# APM32F446 register map
File version: 1.0
CPU: CM4 r0p1, little endian, MPU, FPU, 4 interrupt priority bits
Registers are 32-bit, read-write, reset 0x0 unless marked. A register's access mark holds for its fields unless they carry their own. Offsets are from the block's base; [hi:lo] are bit positions; {n}, {i} and the like mark numbered series.

## CSE_PRAM
Base 0x14001000
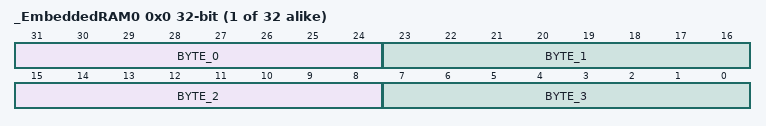
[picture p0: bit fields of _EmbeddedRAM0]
{0x0+4i} _EmbeddedRAM{i} (CSE_PRAM view) (i=0..31) — CSE PRAM {i} Register
  [31-8n:24-8n] BYTE_{n} (n=0..3) — Data byte {n} of Rx/Tx frame.
{0x0+4i} _EmbeddedRAM{i}LL 8-bit (CSE_PRAM view) (i=0..31) — CSE PRAM{i}LL register.
  [7:0] RAM_LL — RAM_LL stores the first 8 bits of the 32 bit CRC
{0x1+4i} _EmbeddedRAM{i}LU 8-bit (i=0..31) — CSE PRAM{i}LU register.
  [7:0] RAM_LU — RAM_LU stores the second 8 bits of the 32 bit CRC
{0x2+4i} _EmbeddedRAM{i}HL 8-bit (i=0..31) — CSE PRAM{i}HL register.
  [7:0] RAM_HL — RAM_HL stores the third 8 bits of the 32 bit CRC
{0x3+4i} _EmbeddedRAM{i}HU 8-bit (i=0..31) — CSE PRAM{i}HU register.
  [7:0] RAM_HU — RAM_HU stores the fourth 8 bits of the 32 bit CRC

## EREP — Error Reporting
Base 0x40018000
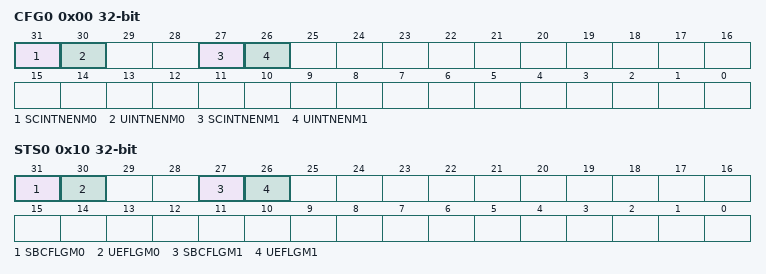
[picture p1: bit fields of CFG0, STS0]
0x00 CFG0 — Configure Register 0
  [31] SCINTNENM0 — Memory 0 Single-Bit Correction Interrupt Notification Enable
    0=Interrupt notification of Memory 0 single-bit correction events is disabled; 1=Interrupt notification of Memory 0 single-bit correction events is enabled
  [30] UINTNENM0 — Memory 0 Uncorrectable Interrupt Notification Enable
    0=Interrupt notification of Memory 0 non-correctable error events is disabled; 1=Interrupt notification of Memory 0 non-correctable error events is enabled
  [27] SCINTNENM1 — Memory 1 Single-Bit Correction Interrupt Notification Enable
    0=Interrupt notification of Memory 1 single-bit correction events is disabled; 1=Interrupt notification of Memory 1 single-bit correction events is enabled
  [26] UINTNENM1 — Memory 1 Uncorrectable Interrupt Notification Enable
    0=Interrupt notification of Memory 1 non-correctable error events is disabled; 1=Interrupt notification of Memory 1 non-correctable error events is enabled
0x10 STS0 — Status Register 0
  [31] SBCFLGM0 — Memory 0 Single-Bit Correction Event Flag
    0=No single-bit correction event on Memory 0 detected; 1=Single-bit correction event on Memory 0 detected
  [30] UEFLGM0 — Memory 0 Uncorrectable Error Event Flag
    0=No non-correctable error event on Memory 0 detected; 1=Non-correctable error event on Memory 0 detected
  [27] SBCFLGM1 — Memory 1 Single-Bit Correction Event Flag
    0=No single-bit correction event on Memory 1 detected; 1=Single-bit correction event on Memory 1 detected
  [26] UEFLGM1 — Memory 1 Uncorrectable Error Event Flag
    0=No non-correctable error event on Memory 1 detected; 1=Non-correctable error event on Memory 1 detected
0x100 EADDR0 ro — Error Address Register 0
  [31:0] EADDR
0x110 EADDR1 ro — Error Address Register 1
  [31:0] EADDR

## EINJ — Error Injection
Base 0x40019000
0x00 CFG — Configure Register
  [0] GEINJEN — Global Error Injection Function Enable
    0=Disabled; 1=Enabled
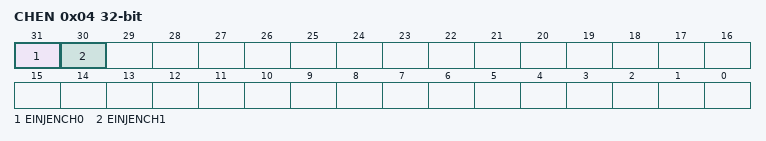
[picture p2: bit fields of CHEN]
0x04 CHEN — Channel Enable Register
  [31] EINJENCH0 — Error Injection CH0 Enable
    0=Error injection is disabled on Error Injection Channel 0; 1=Error injection is enabled on Error Injection Channel 0
  [30] EINJENCH1 — Error Injection CH1 Enable
    0=Error injection is disabled on Error Injection Channel 1; 1=Error injection is enabled on Error Injection Channel 1
0x100 CHD0_WORD0 — Channel Descriptor 0, Word0 Register
  [31:25] CBCBINV — Checkbit Bus Corresponding Bit Invert
0x104 CHD0_WORD1 — Channel Descriptor 0, Word1 Register
  [31:0] DBCBINVB0_3 — Data Bus 0-3 Bytes Corresponding Bit Invert
0x200 CHD1_WORD0 — Channel Descriptor 1, Word0 Register
  [31:25] CBCBINV — Checkbit Bus Corresponding Bit Invert
0x204 CHD1_WORD1 — Channel Descriptor 1, Word1 Register
  [31:0] DBCBINVB0_3 — Data Bus 0-3 Bytes Corresponding Bit Invert

## DMACHM — DMA Memory Access Channel Multiplexer
Base 0x40021000
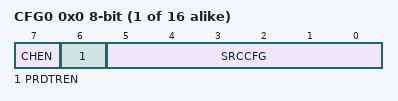
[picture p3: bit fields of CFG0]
{0x0+i} CFG{i} 8-bit (i=0..15) — Channel register {i}
  [7] CHEN — DMA Channel Enable
    0=DMA channel is disabled. This mode is primarily used during configuration of the DMAMux. The DMA has separate channel enables/disables, which should be used to disable or reconfigure a DMA channel.; 1=DMA channel is enabled
  [6] PRDTREN — DMA Channel Periodic Trigger Enable
    0=Triggering is disabled. If triggering is disabled and ENBL is set, the DMA Channel will simply route the specified source to the DMA channel. (Normal mode); 1=Triggering is enabled. If triggering is enabled and ENBL is set, the DMAMUX is in Periodic Trigger mode.
  [5:0] SRCCFG — DMA Channel Source Configure
